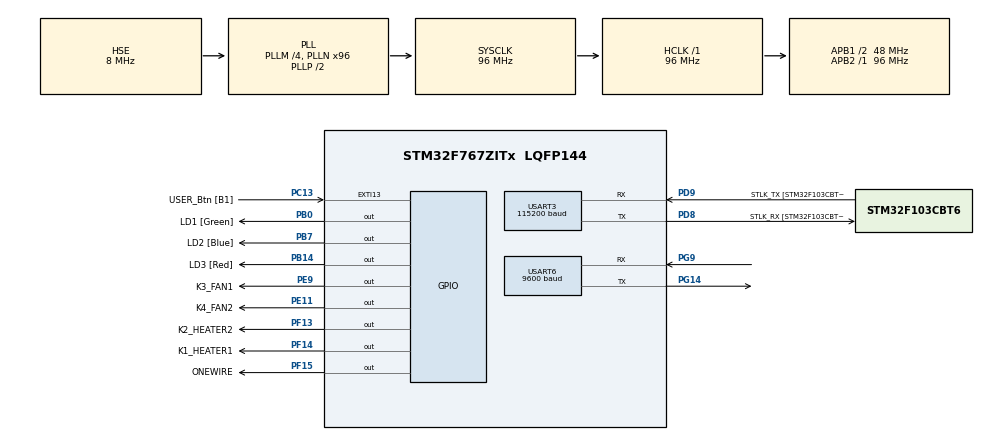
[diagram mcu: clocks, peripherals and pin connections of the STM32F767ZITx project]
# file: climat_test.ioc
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IWDG.Prescaler=IWDG_PRESCALER_64
IWDG.Reload=1999
IWDG.Window=4095
Mcu.Family=STM32F7
Mcu.Name=STM32F767ZITx
Mcu.Package=LQFP144
NVIC.PriorityGroup=NVIC_PRIORITYGROUP_4
NVIC.USART3_IRQn=true\:5\:0\:false\:false\:true\:true\:true\:true
NVIC.USART6_IRQn=true\:5\:0\:false\:false\:true\:true\:true\:true
PA13.GPIO_Label=TMS
PA13.Mode=Serial_Wire
PA13.Signal=SYS_JTMS-SWDIO
PA14.GPIO_Label=TCK
PA14.Mode=Serial_Wire
PA14.Signal=SYS_JTCK-SWCLK
PB0.GPIO_Label=LD1 [Green]
PB0.Signal=GPIO_Output
PB14.GPIO_Label=LD3 [Red]
PB14.Signal=GPIO_Output
PB3.GPIO_Label=SWO
PB3.Signal=SYS_JTDO-SWO
PB7.GPIO_Label=LD2 [Blue]
PB7.Signal=GPIO_Output
PC13.GPIO_Label=USER_Btn [B1]
PC13.Signal=GPXTI13
PC14/OSC32_IN.Mode=LSE-External-Oscillator
PC14/OSC32_IN.Signal=RCC_OSC32_IN
PC15/OSC32_OUT.Mode=LSE-External-Oscillator
PC15/OSC32_OUT.Signal=RCC_OSC32_OUT
PD8.GPIO_Label=STLK_RX [STM32F103CBT6_PA3]
PD8.Mode=Asynchronous
PD8.Signal=USART3_TX
PD9.GPIO_Label=STLK_TX [STM32F103CBT6_PA2]
PD9.Mode=Asynchronous
PD9.Signal=USART3_RX
PE11.GPIO_Label=K4_FAN2
PE11.GPIO_ModeDefaultOutputPP=GPIO_MODE_OUTPUT_PP
PE11.GPIO_PuPd=GPIO_NOPULL
PE11.GPIO_Speed=GPIO_SPEED_FREQ_LOW
PE11.PinState=GPIO_PIN_RESET
PE11.Signal=GPIO_Output
PE9.GPIO_Label=K3_FAN1
PE9.GPIO_ModeDefaultOutputPP=GPIO_MODE_OUTPUT_PP
PE9.GPIO_PuPd=GPIO_NOPULL
PE9.GPIO_Speed=GPIO_SPEED_FREQ_LOW
PE9.PinState=GPIO_PIN_RESET
PE9.Signal=GPIO_Output
PF13.GPIO_Label=K2_HEATER2
PF13.GPIO_ModeDefaultOutputPP=GPIO_MODE_OUTPUT_PP
PF13.GPIO_PuPd=GPIO_NOPULL
PF13.GPIO_Speed=GPIO_SPEED_FREQ_LOW
PF13.PinState=GPIO_PIN_RESET
PF13.Signal=GPIO_Output
PF14.GPIO_Label=K1_HEATER1
PF14.GPIO_ModeDefaultOutputPP=GPIO_MODE_OUTPUT_PP
PF14.GPIO_PuPd=GPIO_NOPULL
PF14.GPIO_Speed=GPIO_SPEED_FREQ_LOW
PF14.PinState=GPIO_PIN_RESET
PF14.Signal=GPIO_Output
PF15.GPIO_Label=ONEWIRE
PF15.GPIO_ModeDefaultOutputPP=GPIO_MODE_OUTPUT_OD
PF15.GPIO_PuPd=GPIO_NOPULL
PF15.GPIO_Speed=GPIO_SPEED_FREQ_LOW
PF15.PinState=GPIO_PIN_SET
PF15.Signal=GPIO_Output
PG14.Mode=Asynchronous
PG14.Signal=USART6_TX
PG9.Mode=Asynchronous
PG9.Signal=USART6_RX
PH0/OSC_IN.GPIO_Label=MCO [STM32F103CBT6_PA8]
PH0/OSC_IN.Mode=HSE-External-Clock-Source
PH0/OSC_IN.Signal=RCC_OSC_IN
PH1/OSC_OUT.Mode=HSE-External-Clock-Source
PH1/OSC_OUT.Signal=RCC_OSC_OUT
ProjectManager.HeapSize=0x0
ProjectManager.StackSize=0x400
ProjectManager.TargetToolchain=STM32CubeIDE
RCC.48MHZClocksFreq_Value=24000000
RCC.AHBFreq_Value=96000000
RCC.APB1CLKDivider=RCC_HCLK_DIV2
RCC.APB1Freq_Value=48000000
RCC.APB1TimFreq_Value=96000000
RCC.APB2Freq_Value=96000000
RCC.APB2TimFreq_Value=96000000
RCC.CortexFreq_Value=96000000
RCC.HCLKFreq_Value=96000000
RCC.HSE_VALUE=8000000
RCC.HSI_VALUE=16000000
RCC.PLLM=4
RCC.PLLMUL=RCC_PLL_MUL9
RCC.PLLN=96
RCC.PLLP=RCC_PLLP_DIV2
RCC.PLLQ=4
RCC.PLLSourceVirtual=RCC_PLLSOURCE_HSE
RCC.PRESCALERUSB=RCC_USBCLKSOURCE_PLL_DIV1_5
RCC.SYSCLKFreq_VALUE=96000000
RCC.SYSCLKSource=RCC_SYSCLKSOURCE_PLLCLK
RCC.SYSCLKSourceVirtual=RCC_SYSCLKSOURCE_PLLCLK
RCC.USBFreq_Value=48000000
RCC.VCOOutputFreq_Value=192000000
USART3.BaudRate=115200
USART3.Mode=MODE_TX_RX
USART3.Parity=PARITY_NONE
USART3.StopBits=STOPBITS_1
USART3.VirtualMode-Asynchronous=VM_ASYNC
USART3.WordLength=WORDLENGTH_8B
USART6.BaudRate=9600
USART6.Mode=MODE_TX_RX
USART6.Parity=PARITY_NONE
USART6.StopBits=STOPBITS_1
USART6.VirtualMode-Asynchronous=VM_ASYNC
USART6.WordLength=WORDLENGTH_8B
VP_IWDG_VS_IWDG.Mode=IWDG_Activate
board=NUCLEO-F767ZI

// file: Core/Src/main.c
/* USER CODE BEGIN Header */
/**
  ******************************************************************************
  * @file           : main.c
  * @brief          : Main program body
  ******************************************************************************
  * @attention
  *
  * Copyright (c) 2026 STMicroelectronics.
  * All rights reserved.
  *
  * This software is licensed under terms that can be found in the LICENSE file
  * in the root directory of this software component.
  * If no LICENSE file comes with this software, it is provided AS-IS.
  *
  ******************************************************************************
  */
/* USER CODE END Header */
#include "main.h"

/* USER CODE BEGIN Includes */
#include "sensor_stage1.h"
/* USER CODE END Includes */

IWDG_HandleTypeDef hiwdg;

UART_HandleTypeDef huart3;
UART_HandleTypeDef huart6;

void SystemClock_Config(void);
static void MX_GPIO_Init(void);
static void MX_USART3_UART_Init(void);
static void MX_USART6_UART_Init(void);
static void MX_IWDG_Init(void);

int main(void)
{

  /* MCU Configuration--------------------------------------------------------*/

  /* Reset of all peripherals, Initializes the Flash interface and the Systick. */
  HAL_Init();

  /* Configure the system clock */
  SystemClock_Config();

  /* Initialize all configured peripherals */
  MX_GPIO_Init();
  MX_USART3_UART_Init();
  MX_USART6_UART_Init();
  MX_IWDG_Init();
  /* USER CODE BEGIN 2 */
  sensor_stage1_init();
  /* USER CODE END 2 */

  /* Infinite loop */
  while (1)
  {

    /* USER CODE BEGIN 3 */
    sensor_stage1_poll();
  }
  /* USER CODE END 3 */
}

void SystemClock_Config(void)
{
  RCC_OscInitTypeDef RCC_OscInitStruct = {0};
  RCC_ClkInitTypeDef RCC_ClkInitStruct = {0};

  /** Configure LSE Drive Capability
  */
  HAL_PWR_EnableBkUpAccess();

  /** Configure the main internal regulator output voltage
  */
  __HAL_RCC_PWR_CLK_ENABLE();
  __HAL_PWR_VOLTAGESCALING_CONFIG(PWR_REGULATOR_VOLTAGE_SCALE3);

  /** Initializes the RCC Oscillators according to the specified parameters
  * in the RCC_OscInitTypeDef structure.
  */
  RCC_OscInitStruct.OscillatorType = RCC_OSCILLATORTYPE_LSI|RCC_OSCILLATORTYPE_HSE;
  RCC_OscInitStruct.HSEState = RCC_HSE_BYPASS;
  RCC_OscInitStruct.LSIState = RCC_LSI_ON;
  RCC_OscInitStruct.PLL.PLLState = RCC_PLL_ON;
  RCC_OscInitStruct.PLL.PLLSource = RCC_PLLSOURCE_HSE;
  RCC_OscInitStruct.PLL.PLLM = 4;
  RCC_OscInitStruct.PLL.PLLN = 96;
  RCC_OscInitStruct.PLL.PLLP = RCC_PLLP_DIV2;
  RCC_OscInitStruct.PLL.PLLQ = 4;
  RCC_OscInitStruct.PLL.PLLR = 2;
  if (HAL_RCC_OscConfig(&RCC_OscInitStruct) != HAL_OK)
  {
    Error_Handler();
  }

  /** Activate the Over-Drive mode
  */
  if (HAL_PWREx_EnableOverDrive() != HAL_OK)
  {
    Error_Handler();
  }

  /** Initializes the CPU, AHB and APB buses clocks
  */
  RCC_ClkInitStruct.ClockType = RCC_CLOCKTYPE_HCLK|RCC_CLOCKTYPE_SYSCLK
                              |RCC_CLOCKTYPE_PCLK1|RCC_CLOCKTYPE_PCLK2;
  RCC_ClkInitStruct.SYSCLKSource = RCC_SYSCLKSOURCE_PLLCLK;
  RCC_ClkInitStruct.AHBCLKDivider = RCC_SYSCLK_DIV1;
  RCC_ClkInitStruct.APB1CLKDivider = RCC_HCLK_DIV2;
  RCC_ClkInitStruct.APB2CLKDivider = RCC_HCLK_DIV1;

  if (HAL_RCC_ClockConfig(&RCC_ClkInitStruct, FLASH_LATENCY_3) != HAL_OK)
  {
    Error_Handler();
  }
}

static void MX_IWDG_Init(void)
{

  hiwdg.Instance = IWDG;
  hiwdg.Init.Prescaler = IWDG_PRESCALER_64;
  hiwdg.Init.Window = 4095;
  hiwdg.Init.Reload = 1999;
  if (HAL_IWDG_Init(&hiwdg) != HAL_OK)
  {
    Error_Handler();
  }

}

static void MX_USART3_UART_Init(void)
{

  huart3.Instance = USART3;
  huart3.Init.BaudRate = 115200;
  huart3.Init.WordLength = UART_WORDLENGTH_8B;
  huart3.Init.StopBits = UART_STOPBITS_1;
  huart3.Init.Parity = UART_PARITY_NONE;
  huart3.Init.Mode = UART_MODE_TX_RX;
  huart3.Init.HwFlowCtl = UART_HWCONTROL_NONE;
  huart3.Init.OverSampling = UART_OVERSAMPLING_16;
  huart3.Init.OneBitSampling = UART_ONE_BIT_SAMPLE_DISABLE;
  huart3.AdvancedInit.AdvFeatureInit = UART_ADVFEATURE_NO_INIT;
  if (HAL_UART_Init(&huart3) != HAL_OK)
  {
    Error_Handler();
  }

}

static void MX_USART6_UART_Init(void)
{

  huart6.Instance = USART6;
  huart6.Init.BaudRate = 9600;
  huart6.Init.WordLength = UART_WORDLENGTH_8B;
  huart6.Init.StopBits = UART_STOPBITS_1;
  huart6.Init.Parity = UART_PARITY_NONE;
  huart6.Init.Mode = UART_MODE_TX_RX;
  huart6.Init.HwFlowCtl = UART_HWCONTROL_NONE;
  huart6.Init.OverSampling = UART_OVERSAMPLING_16;
  huart6.Init.OneBitSampling = UART_ONE_BIT_SAMPLE_DISABLE;
  huart6.AdvancedInit.AdvFeatureInit = UART_ADVFEATURE_NO_INIT;
  if (HAL_UART_Init(&huart6) != HAL_OK)
  {
    Error_Handler();
  }

}

static void MX_GPIO_Init(void)
{
  GPIO_InitTypeDef GPIO_InitStruct = {0};

  /* GPIO Ports Clock Enable */
  __HAL_RCC_GPIOC_CLK_ENABLE();
  __HAL_RCC_GPIOH_CLK_ENABLE();
  __HAL_RCC_GPIOB_CLK_ENABLE();
  __HAL_RCC_GPIOF_CLK_ENABLE();
  __HAL_RCC_GPIOE_CLK_ENABLE();
  __HAL_RCC_GPIOD_CLK_ENABLE();
  __HAL_RCC_GPIOA_CLK_ENABLE();
  __HAL_RCC_GPIOG_CLK_ENABLE();

  /*Configure GPIO pin Output Level */
  HAL_GPIO_WritePin(GPIOB, LD1_Pin|LD3_Pin|LD2_Pin, GPIO_PIN_RESET);

  /*Configure GPIO pin Output Level */
  HAL_GPIO_WritePin(GPIOF, K2_HEATER2_Pin|K1_HEATER1_Pin, GPIO_PIN_RESET);

  /*Configure GPIO pin Output Level */
  HAL_GPIO_WritePin(ONEWIRE_GPIO_Port, ONEWIRE_Pin, GPIO_PIN_SET);

  /*Configure GPIO pin Output Level */
  HAL_GPIO_WritePin(GPIOE, K3_FAN1_Pin|K4_FAN2_Pin, GPIO_PIN_RESET);

  /*Configure GPIO pin : USER_Btn_Pin */
  GPIO_InitStruct.Pin = USER_Btn_Pin;
  GPIO_InitStruct.Mode = GPIO_MODE_IT_RISING;
  GPIO_InitStruct.Pull = GPIO_NOPULL;
  HAL_GPIO_Init(USER_Btn_GPIO_Port, &GPIO_InitStruct);

  /*Configure GPIO pins : LD1_Pin LD3_Pin LD2_Pin */
  GPIO_InitStruct.Pin = LD1_Pin|LD3_Pin|LD2_Pin;
  GPIO_InitStruct.Mode = GPIO_MODE_OUTPUT_PP;
  GPIO_InitStruct.Pull = GPIO_NOPULL;
  GPIO_InitStruct.Speed = GPIO_SPEED_FREQ_LOW;
  HAL_GPIO_Init(GPIOB, &GPIO_InitStruct);

  /*Configure GPIO pins : K2_HEATER2_Pin K1_HEATER1_Pin */
  GPIO_InitStruct.Pin = K2_HEATER2_Pin|K1_HEATER1_Pin;
  GPIO_InitStruct.Mode = GPIO_MODE_OUTPUT_PP;
  GPIO_InitStruct.Pull = GPIO_NOPULL;
  GPIO_InitStruct.Speed = GPIO_SPEED_FREQ_LOW;
  HAL_GPIO_Init(GPIOF, &GPIO_InitStruct);

  /*Configure shared 1-Wire bus: HIGH releases the external pull-up. */
  GPIO_InitStruct.Pin = ONEWIRE_Pin;
  GPIO_InitStruct.Mode = GPIO_MODE_OUTPUT_OD;
  GPIO_InitStruct.Pull = GPIO_NOPULL;
  GPIO_InitStruct.Speed = GPIO_SPEED_FREQ_LOW;
  HAL_GPIO_Init(ONEWIRE_GPIO_Port, &GPIO_InitStruct);

  /*Configure GPIO pins : K3_FAN1_Pin K4_FAN2_Pin */
  GPIO_InitStruct.Pin = K3_FAN1_Pin|K4_FAN2_Pin;
  GPIO_InitStruct.Mode = GPIO_MODE_OUTPUT_PP;
  GPIO_InitStruct.Pull = GPIO_NOPULL;
  GPIO_InitStruct.Speed = GPIO_SPEED_FREQ_LOW;
  HAL_GPIO_Init(GPIOE, &GPIO_InitStruct);

}

void Error_Handler(void)
{
  __disable_irq();
  while (1)
  {
  }
}
